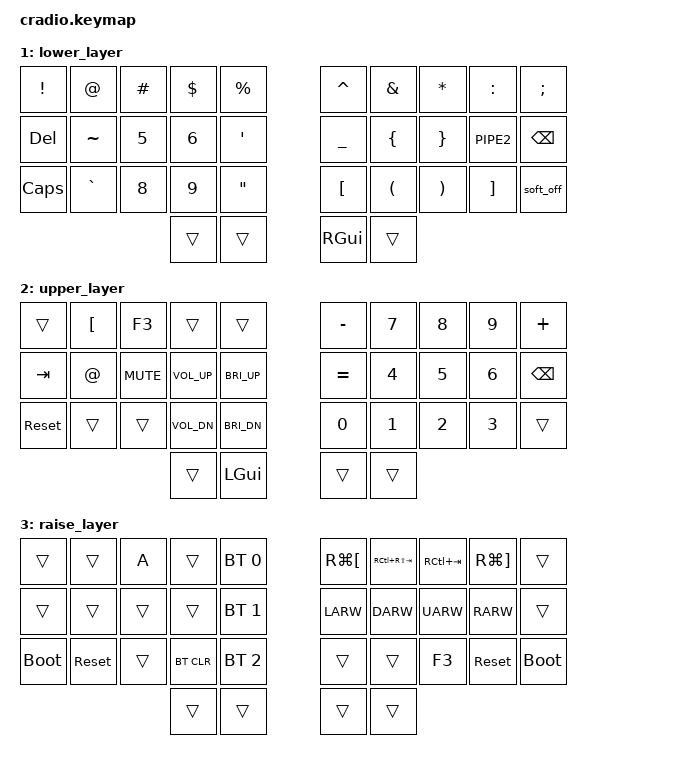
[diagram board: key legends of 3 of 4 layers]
// Copyright (c) 2022 The ZMK Contributors
// SPDX-License-Identifier: MIT

#include <behaviors.dtsi>
#include <dt-bindings/zmk/keys.h>
#include <dt-bindings/zmk/bt.h>
#include <dt-bindings/zmk/ext_power.h>

// Home row mods macro
#define HRML(k1,k2,k3,k4) &ht LSHFT k1  &ht LALT k2  &ht LCTRL k3  &ht LGUI k4
#define HRMR(k1,k2,k3,k4) &ht RGUI k1  &ht RCTRL k2  &ht RALT k3  &ht RSHFT k4

#define DEFAULT 0
#define LOWER 1
#define UPPER 2
#define RAISE 3

/ {
    behaviors {
        ht: hold_tap {
            compatible = "zmk,behavior-hold-tap";
            #binding-cells = <2>;
            flavor = "tap-preferred";
            tapping-term-ms = <220>;
            quick-tap-ms = <150>;
            require-prior-idle-ms = <100>;
            bindings = <&kp>, <&kp>;
        };
    };

    keymap {
        compatible = "zmk,keymap";
        wakeup-sources = <&kp SPACE &kp ENTER>;
        default_layer {
            bindings = <
        //╭──────────┬──────────┬──────────┬──────────┬──────────╮   ╭──────────┬──────────┬──────────┬──────────┬──────────╮
        //│  Q       │  W       │  E       │  R       │  T       │   │  Y       │  U       │  I       │  O       │  P       │
            &kp Q      &kp W      &kp E      &kp R      &kp T          &kp Y      &kp U      &kp I      &kp O      &kp P
        //├──────────┼──────────┼──────────┼──────────┼──────────┤   ├──────────┼──────────┼──────────┼──────────┼──────────┤
        //│  A       │  S       │  D       │  F       │  G       │   │  H       │  J       │  K       │  L       │ ' "      │
            HRML(A,        S,         D,         F)     &kp G          &kp H      HRMR(J,        K,         L,        BSPC)
        //├──────────┼──────────┼──────────┼──────────┼──────────┤   ├──────────┼──────────┼──────────┼──────────┼──────────┤
        //│  Z       │  X       │  C       │  V       │  B       │   │  N       │  M       │ , <      │ . >      │ / ?      │
            &kp Z      &kp X      &kp C      &kp V      &kp B          &kp N      &kp M      &kp COMMA  &kp DOT    &kp FSLH
        //╰──────────┴──────────┴──────────┼──────────┼──────────┤   ├──────────┼──────────┼──────────┴──────────┴──────────╯
                                            &lt 1 ESC   &kp SPACE     &lt 2 ENTER &mo 3
        //                                 ╰──────────┴──────────╯   ╰──────────┴──────────╯
            >;
        };

        lower_layer {
            bindings = <
        //╭──────────┬──────────┬──────────┬──────────┬──────────╮   ╭──────────┬──────────┬──────────┬──────────┬──────────╮
        //│ !        │ @        │ #        │ $        │ %        │   │ ^        │ &        │ *        │ :        │  ;       │
           &kp EXCL   &kp AT     &kp HASH   &kp DLLR   &kp PRCNT     &kp CARET  &kp AMPS   &kp STAR   &kp COLON  &kp SEMI
        //├──────────┼──────────┼──────────┼──────────┼──────────┤   ├──────────┼──────────┼──────────┼──────────┼──────────┤
        //│ DELETE   │ ~        │          │          │ '        │   │ _        │ {        │ }        │ |        │          │
            &kp DEL   &kp TILDE  &kp N5     &kp N6     &kp SQT        &kp UNDER  &kp LBRC   &kp RBRC   &kp PIPE2  &kp BSPC
        //├──────────┼──────────┼──────────┼──────────┼──────────┤   ├──────────┼──────────┼──────────┼──────────┼──────────┤
        //│ CAPS     │  `       │  8       │  9       │ "        │   │ [        │ (        │ )        │ ]        │SOFT OFF  │
           &kp CAPS   &kp GRAVE &kp N8     &kp N9     &kp DQT       &kp LBKT    &kp LPAR  &kp RPAR   &kp RBKT     &soft_off
        //╰──────────┴──────────┴──────────┼──────────┼──────────┤   ├──────────┼──────────┼──────────┴──────────┴──────────╯
                                             &trans     &trans        &kp RGUI   &trans
        //                                 ╰──────────┴──────────╯   ╰──────────┴──────────╯
            >;
        };

        upper_layer {
            bindings = <
        //╭──────────┬──────────┬──────────┬──────────┬──────────╮   ╭──────────┬──────────┬──────────┬──────────┬──────────╮
        //│          │  [       │          │          │          │   │  -       │  7       │  8       │  9       │  +       │
            &trans     &kp LBKT   &kp F3    &trans       &trans         &kp MINUS  &kp N7    &kp N8    &kp N9      &kp PLUS
        //├──────────┼──────────┼──────────┼──────────┼──────────┤   ├──────────┼──────────┼──────────┼──────────┼──────────┤
        //│          │  @       │          │          │          │   │ =        │  4       │  5       │  6       │          │
            &kp TAB   &kp AT      &kp C_MUTE &kp C_VOL_UP &kp C_BRI_UP &kp EQUAL  &kp N4     &kp N5     &kp N6     &kp BSPC
        //├──────────┼──────────┼──────────┼──────────┼──────────┤   ├──────────┼──────────┼──────────┼──────────┼──────────┤
        //│ RESET    │          │          │          │          │   │ 0        │  1       │ 2        │  3       │          │
           &sys_reset &trans     &trans     &kp C_VOL_DN &kp C_BRI_DN &kp N0     &kp N1     &kp N2     &kp N3     &trans
        //╰──────────┴──────────┴──────────┼──────────┼──────────┤   ├──────────┼──────────┼──────────┴──────────┴──────────╯
                                             &trans     &kp LGUI         &trans     &trans
        //                                 ╰──────────┴──────────╯   ╰──────────┴──────────╯
            >;
        };

        raise_layer {
            bindings = <
        //╭──────────┬──────────┬──────────┬──────────┬──────────╮   ╭──────────┬──────────┬──────────┬──────────┬──────────╮
        //│          │          │          │          │PROFILE 0 │   │ BACK     │ Next Tab │          │          │          │
           &trans     &trans     &kp A      &trans    &bt BT_SEL 0   &kp RG(LBKT) &kp RC(RS(TAB)) &kp RC(TAB) &kp RG(RBKT) &trans
        //├──────────┼──────────┼──────────┼──────────┼──────────┤   ├──────────┼──────────┼──────────┼──────────┼──────────┤
        //│          │          │          │          │PROFILE 1 │   │ LEFT     │ DOWN     │ UP       │ RIGHT    │          │
           &trans     &trans     &trans     &trans    &bt BT_SEL 1    &kp LARW   &kp DARW   &kp UARW   &kp RARW   &trans
        //├──────────┼──────────┼──────────┼──────────┼──────────┤   ├──────────┼──────────┼──────────┼──────────┼──────────┤
        //│BOOTLOADER│RESET     │          │ CLEAR BT │PROFILE 2 │   │          │          │ F3       │RESET     │BOOTLOADER│
           &bootloader &sys_reset &trans    &bt BT_CLR &bt BT_SEL 2    &trans     &trans     &kp F3    &sys_reset &bootloader
        //╰──────────┴──────────┴──────────┼──────────┼──────────┤   ├──────────┼──────────┼──────────┴──────────┴──────────╯
                                             &trans     &trans         &trans     &trans
        //                                 ╰──────────┴──────────╯   ╰──────────┴──────────╯
            >;
        };
    };
};
